# CM41x_M0 register map
Vendor: Analog Devices; Series: CM41x_M0; File version: 1p0
CPU: CM0 r0p0, little endian, MPU, FPU, 4 interrupt priority bits
Registers are 32-bit, read-write, reset 0x0 unless marked. A register's access mark holds for its fields unless they carry their own. Offsets are from the block's base; [hi:lo] are bit positions; {n}, {i} and the like mark numbered series; <NAME> marks a mode.

## UART0 — UART
Base 0x4100A000
Same registers: UART1 0x40044000, UART2 0x40045000, UART3 0x40046000, UART4 0x40047000
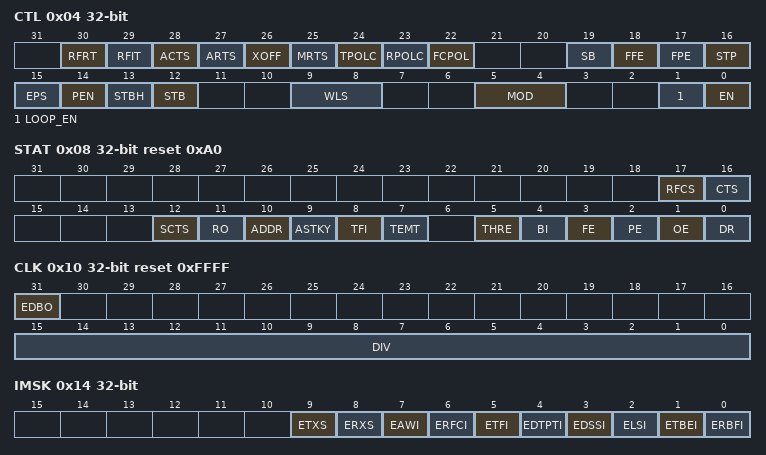
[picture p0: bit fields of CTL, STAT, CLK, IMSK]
0x04 CTL — Control Register
  [30] RFRT — Receive FIFO RTS Threshold
    0=RX_RTS_TH4 (Deassert RTS if RX FIFO word count > 4; assert if <= 4); 1=RX_RTS_TH7 (Deassert RTS if RX FIFO word count > 7; assert if <= 7)
  [29] RFIT — Receive FIFO IRQ Threshold
    0=RX_IRQ_TH4 (Set RFCS=1 if RX FIFO count >= 4); 1=RX_IRQ_TH7 (Set RFCS=1 if RX FIFO count >= 7)
  [28] ACTS — Automatic CTS
    0=CTS_MAN (Disable TX handshaking protocol); 1=CTS_AUTO (Enable TX handshaking protocol)
  [27] ARTS — Automatic RTS
    0=RTS_MAN (Disable RX handshaking protocol.); 1=RTS_AUTO (Enable RX handshaking protocol.)
  [26] XOFF — Transmitter off
    0=TX_ON (Transmission ON, if ACTS=0); 1=TX_OFF (Transmission OFF, if ACTS=0)
  [25] MRTS — Manual Request to Send
    0=RTS_DEASSERT (Deassert RTS pin when ARTS=0); 1=RTS_ASSERT (Assert RTS pin when ARTS=0)
  [24] TPOLC — IrDA TX Polarity Change
    0=TPOLC_LO (Active-low TX polarity setting); 1=TPOLC_HI (Active-high TX polarity setting)
  [23] RPOLC — IrDA RX Polarity Change
    0=RPOLC_LO (Active-low RX polarity setting); 1=RPOLC_HI (Active-high RX polarity setting)
  [22] FCPOL — Flow Control Pin Polarity
    0=FCPOL_LO (Active low CTS/RTS); 1=FCPOL_HI (Active high CTS/RTS)
  [19] SB — Set Break
    0=NORM_BREAK (No force); 1=FORCE_BREAK (Force TX pin to 0)
  [18] FFE — Force Framing Error on Transmit
    0=NORM_FRM_ERR (Normal operation); 1=FORCE_FRM_ERR (Force error)
  [17] FPE — Force Parity Error on Transmit
    0=NORM_PARITY_ERR (Normal operation); 1=FORCE_PARITY_ERR (Force parity error)
  [16] STP — Sticky Parity
    0=NORM_PARITY (No forced parity); 1=STICKY_PARITY (Force (Stick) parity to defined value (if PEN=1))
  [15] EPS — Even Parity Select
    0=ODD_PARITY; 1=EVEN_PARITY
  [14] PEN — Parity Enable
    0=PARITY_DIS (Disable); 1=PARITY_EN (Enable parity transmit and check)
  [13] STBH — Stop Bits (Half Bit Time)
    0=NO_EXTRA_STBH (0 half-bit-time stop bit); 1=ONE_EXTRA_STBH (1 half-bit-time stop bit)
  [12] STB — Stop Bits
    0=NO_EXTRA_STB (1 stop bit); 1=ONE_EXTRA_STB (2 stop bits)
  [9:8] WLS — Word Length Select
    {v}=WL{v+5}BITS ({v+5}-bit word) (v=0..3)
  [5:4] MOD — Mode of Operation
    0=UART_MODE; 1=MDB_MODE; 2=IRDA_MODE (IrDA SIR mode)
  [1] LOOP_EN — Loopback Enable
    0=LOOP_DIS (Disable); 1=LOOP_EN (Enable)
  [0] EN — Enable UART
    0=CLK_DIS (Disable); 1=CLK_EN (Enable)
0x08 STAT reset 0xA0 — Status Register
  [17] RFCS ro — Receive FIFO Count Status
    0=RFCS_LO (RX FIFO has less than 4 (7) entries when RFIT=0 (1)); 1=RFCS_HI (RX FIFO has at least 4 (7) entries when RFIT=0 (1))
  [16] CTS ro — Clear to Send
    0=CTS_LO (Not clear to send (External device not ready to receive)); 1=CTS_HI (Clear to send (External device ready to receive))
  [12] SCTS — Sticky CTS
    0=CTS_LO_STKY (CTS has not transitioned from low to high); 1=CTS_HI_STKY (CTS has transitioned from low to high)
  [11] RO ro — Reception On-going
    0=NO_RX_PROGRESS (No data reception in progress); 1=RX_PROGRESS (Data reception in progress)
  [10] ADDR — Address Bit Status
    0=ADDR_LO (Address bit is low); 1=ADDR_HI (Address bit is high)
  [9] ASTKY — Address Sticky
    0=ADDR_LO_STKY (ADDR bit has not been set); 1=ADDR_HI_STKY (ADDR bit has been set)
  [8] TFI — Transmission Finished Indicator
    0=TX_NOT_DONE (TEMT did not transition from 0 to 1); 1=TX_DONE (TEMT transition from 0 to 1)
  [7] TEMT ro — TSR and THR Empty
    0=TX_NOT_EMPTY (Not empty TSR/THR); 1=TX_EMPTY (TSR/THR Empty)
  [5] THRE ro — Transmit Hold Register Empty
    0=THR_NOT_EMPTY (Not empty THR/TAIP); 1=THR_EMPTY (Empty THR/TAIP)
  [4] BI — Break Indicator
    0=NO_BREAK_INT (No break interrupt); 1=BREAK_INT (Break interrupt)
  [3] FE — Framing Error
    0=NO_FRAMING_ERR (No error); 1=FRAMING_ERR (Invalid stop bit error)
  [2] PE — Parity Error
    0=NO_PARITY_ERR (No parity error); 1=PARITY_ERR (Parity error)
  [1] OE — Overrun Error
    0=NO_OVR_ERR (No overrun); 1=OVR_ERR (Overrun error)
  [0] DR ro — Data Ready
    0=NO_DATA (No new data); 1=NEW_DATA (New data in RBR)
0x0C SCR — Scratch Register
  [7:0] VALUE range 0x00000000..0x000000FF — Stored 8-bit Data
0x10 CLK reset 0xFFFF — Clock Rate Register
  [31] EDBO — Enable Divide By One
    0=DIS_DIV_BY_ONE (Bit clock prescaler = 16); 1=EN_DIV_BY_ONE (Bit clock prescaler = 1)
  [15:0] DIV range 0x00000000..0x0000FFFF — Divisor
0x14 IMSK — Interrupt Mask Register
  [9] ETXS — Enable TX to Status Interrupt Mask Status
    0=ETXS_LO (Interrupt is masked); 1=ETXS_HI (Interrupt is unmasked)
  [8] ERXS — Enable RX to Status Interrupt Mask Status
    0=ERXS_LO (Interrupt is masked); 1=ERXS_HI (Interrupt is unmasked)
  [7] EAWI — Enable Address Word Interrupt Mask Status
    0=EAWI_LO (Interrupt is masked); 1=EAWI_HI (Interrupt is unmasked)
  [6] ERFCI — Enable Receive FIFO Count Interrupt Mask Status
    0=ERFCI_LO (Interrupt is masked); 1=ERFCI_HI (Interrupt is unmasked)
  [5] ETFI — Enable Transmission Finished Interrupt Mask Status
    0=ETFI_LO (Interrupt is masked); 1=ETFI_HI (Interrupt is unmasked)
  [4] EDTPTI — Enable DMA TX Peripheral Triggered Interrupt Mask Status
    0=EDTPTI_LO (Interrupt is masked); 1=EDTPTI_HI (Interrupt is unmasked)
  [3] EDSSI — Enable Modem Status Interrupt Mask Status
    0=EDSSI_LO (Interrupt is masked); 1=EDSSI_HI (Interrupt is unmasked)
  [2] ELSI — Enable Line Status Interrupt Mask Status
    0=ELSI_LO (Interrupt is masked); 1=ELSI_HI (Interrupt is unmasked)
  [1] ETBEI — Enable Transmit Buffer Empty Interrupt Mask Status
    0=ETBEI_LO (Interrupt is masked); 1=ETBEI_HI (Interrupt is unmasked)
  [0] ERBFI — Enable Receive Buffer Full Interrupt Mask Status
    0=ERBFI_LO (Interrupt is masked); 1=ERBFI_HI (Interrupt is unmasked)
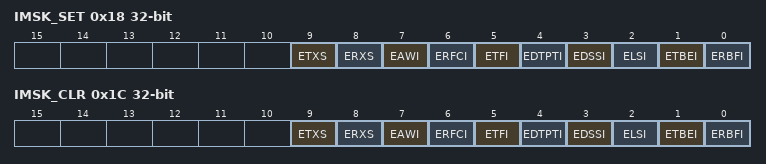
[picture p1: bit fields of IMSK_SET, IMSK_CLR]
0x18 IMSK_SET — Interrupt Mask Set Register
  [9] ETXS — Enable TX to Status Interrupt Mask Set
  [8] ERXS — Enable RX to Status Interrupt Mask Set
  [7] EAWI — Enable Address Word Interrupt Mask Set
  [6] ERFCI — Enable Receive FIFO Count Interrupt Mask Set
  [5] ETFI — Enable Transmission Finished Interrupt Mask Set
  [4] EDTPTI — Enable DMA TX Peripheral Triggered Interrupt Mask Set
  [3] EDSSI — Enable Modem Status Interrupt Mask Set
  [2] ELSI — Enable Line Status Interrupt Mask Set
  [1] ETBEI — Enable Transmit Buffer Empty Interrupt Mask Set
  [0] ERBFI — Enable Receive Buffer Full Interrupt Mask Set
0x1C IMSK_CLR — Interrupt Mask Clear Register
  [9] ETXS — Enable TX to Status Interrupt Mask Clear
  [8] ERXS — Enable RX to Status Interrupt Mask Clear
  [7] EAWI — Enable Address Word Interrupt Mask Clear
  [6] ERFCI — Enable Receive FIFO Count Interrupt Mask Clear
  [5] ETFI — Enable Transmission Finished Interrupt Mask Clear
  [4] EDTPTI — Enable DMA TX Peripheral Triggered Interrupt Mask Clear
  [3] EDSSI — Enable Modem Status Interrupt Mask Clear
  [2] ELSI — Enable Line Status Interrupt Mask Clear
  [1] ETBEI — Enable Transmit Buffer Empty Interrupt Mask Clear
  [0] ERBFI — Enable Receive Buffer Full Interrupt Mask Clear
0x20 RBR — Receive Buffer Register
  [7:0] VALUE ro — 8-bit data
0x24 THR — Transmit Hold Register
  [7:0] VALUE range 0x00000000..0x000000FF — 8 bit data
0x28 TAIP — Transmit Address/Insert Pulse Register
  [7:0] VALUE range 0x00000000..0x000000FF — 8-bit data
0x2C TSR reset 0x7FF — Transmit Shift Register
  [10:0] VALUE ro — Contents of TSR
0x30 RSR — Receive Shift Register
  [9:0] VALUE ro — Contents of RSR
0x34 TXCNT — Transmit Counter Register
  [15:0] VALUE ro — 16-bit Counter Value
0x38 RXCNT — Receive Counter Register
  [15:0] VALUE ro — 16-bit Counter Value
